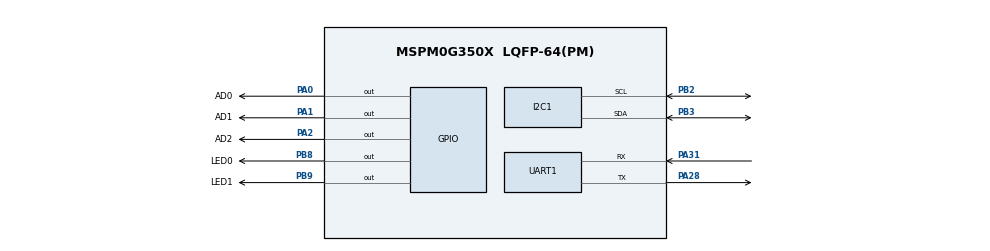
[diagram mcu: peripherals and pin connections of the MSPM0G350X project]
/**
 * ICM42688 软I2C + OLED 硬I2C1 — 地猛星 MSPM0G3507
 * OLED: I2C1, PB2=SCL, PB3=SDA, 地址0x3C
 * ICM: PA15=SCL, PA14=SDA, PA13=CS, PA16=AD0
 *
 * @cliArgs --device "MSPM0G350X" --part "Default" --package "LQFP-64(PM)"
 *            --product "mspm0_sdk@2.11.00.07"
 *             --product "mspm0_sdk@2.11.00.07"
 * @versions {"tool":"1.26.2+4477"}
 */

const GPIO    = scripting.addModule("/ti/driverlib/GPIO", {}, false);
const GPIO1   = GPIO.addInstance();     // LED
const GPIO2   = GPIO.addInstance();     // ICM_CS
const GPIO3   = GPIO.addInstance();     // ICM_SCL
const GPIO4   = GPIO.addInstance();     // ICM_SDA
const GPIO5   = GPIO.addInstance();     // ICM_AD0
const GPIO6   = GPIO.addInstance();     // GRAY address pins
const I2C     = scripting.addModule("/ti/driverlib/I2C", {}, false);
const I2C1    = I2C.addInstance();      // OLED
const SYSCTL  = scripting.addModule("/ti/driverlib/SYSCTL");
const SYSTICK = scripting.addModule("/ti/driverlib/SYSTICK");
const UART    = scripting.addModule("/ti/driverlib/UART", {}, false);
const UART1   = UART.addInstance();     // PRINT
const ADC12   = scripting.addModule("/ti/driverlib/ADC12", {}, false);
const ADC121  = ADC12.addInstance();    // GRAY_ADC

/* ========== 时钟 ========== */
const divider6       = system.clockTree["PLL_CLK2X_DIV"];
divider6.divideValue = 4;
const divider7       = system.clockTree["PLL_PDIV"];
divider7.divideValue = 2;
const divider9       = system.clockTree["UDIV"];
divider9.divideValue = 2;
const gate7  = system.clockTree["MFCLKGATE"];
gate7.enable = true;
const multiplier2         = system.clockTree["PLL_QDIV"];
multiplier2.multiplyValue = 10;
const mux8       = system.clockTree["HSCLKMUX"];
mux8.inputSelect = "HSCLKMUX_SYSPLL2X";

SYSCTL.forceDefaultClkConfig = true;
SYSCTL.clockTreeEn           = true;

const Board = scripting.addModule("/ti/driverlib/Board", {}, false);

/* ========== GPIO1: LED ========== */
GPIO1.$name                         = "LED";
GPIO1.associatedPins.create(2);
GPIO1.associatedPins[0].$name       = "LED0";
GPIO1.associatedPins[0].pin.$assign = "PB8";
GPIO1.associatedPins[1].$name       = "LED1";
GPIO1.associatedPins[1].pin.$assign = "PB9";

/* ========== GPIO2: ICM_CS (PA13, 输出HIGH→I2C模式) ========== */
GPIO2.$name                         = "ICM_CS";
GPIO2.port                          = "PORTA";
GPIO2.associatedPins[0].$name       = "CS";
GPIO2.associatedPins[0].assignedPin = "13";

/* ========== GPIO3: ICM_SCL (PA15, 软I2C时钟) ========== */
GPIO3.$name                         = "ICM_SCL";
GPIO3.port                          = "PORTA";
GPIO3.associatedPins[0].$name       = "SCL";
GPIO3.associatedPins[0].assignedPin = "15";

/* ========== GPIO4: ICM_SDA (PA14, 软I2C数据) ========== */
GPIO4.$name                         = "ICM_SDA";
GPIO4.port                          = "PORTA";
GPIO4.associatedPins[0].$name       = "SDA";
GPIO4.associatedPins[0].assignedPin = "14";

/* ========== GPIO5: ICM_AD0 (PA16, 输出LOW→地址0x68) ========== */
GPIO5.$name                         = "ICM_AD0";
GPIO5.port                          = "PORTA";
GPIO5.associatedPins[0].$name       = "AD0";
GPIO5.associatedPins[0].assignedPin = "16";

/* ========== GPIO6: 灰度模块通道地址 (PA0/PA1/PA2) ========== */
GPIO6.$name                         = "GRAY_ADDR";
GPIO6.port                          = "PORTA";
GPIO6.associatedPins.create(3);
GPIO6.associatedPins[0].$name       = "AD0";
GPIO6.associatedPins[0].assignedPin = "0";
GPIO6.associatedPins[0].pin.$assign = "PA0";
GPIO6.associatedPins[1].$name       = "AD1";
GPIO6.associatedPins[1].assignedPin = "1";
GPIO6.associatedPins[1].pin.$assign = "PA1";
GPIO6.associatedPins[2].$name       = "AD2";
GPIO6.associatedPins[2].assignedPin = "2";
GPIO6.associatedPins[2].pin.$assign = "PA2";

/* ========== ADC0: 灰度模块 OUT (PA27 / ADC channel 0) ========== */
ADC121.$name                      = "GRAY_ADC";
ADC121.sampClkSrc                 = "DL_ADC12_CLOCK_ULPCLK";
ADC121.sampClkDiv                 = "DL_ADC12_CLOCK_DIVIDE_8";
ADC121.adcMem0chansel             = "DL_ADC12_INPUT_CHAN_0";
ADC121.adcMem0_name               = "GRAY_ADC_MEM";
ADC121.sampleTime0                = "25 us";
ADC121.powerDownMode              = "DL_ADC12_POWER_DOWN_MODE_MANUAL";
ADC121.peripheral.$assign         = "ADC0";
ADC121.peripheral.adcPin0.$assign = "PA27";

/* ========== I2C1: OLED (PB2=SCL, PB3=SDA) ========== */
I2C1.$name                             = "OLED";
I2C1.basicEnableController             = true;
I2C1.advDigitalGlitchFilter            = "CLOCKS_1";
I2C1.advControllerRXFIFOTRIG           = "BYTES_8";
I2C1.advControllerTXFIFOTRIG           = "BYTES_7";
I2C1.peripheral.$assign                = "I2C1";
I2C1.peripheral.sdaPin.$assign         = "PB3";
I2C1.peripheral.sclPin.$assign         = "PB2";
I2C1.sdaPinConfig.$name                = "ti_driverlib_gpio_GPIOPinGeneric2";
I2C1.sdaPinConfig.hideOutputInversion  = scripting.forceWrite(false);
I2C1.sdaPinConfig.onlyInternalResistor = scripting.forceWrite(false);
I2C1.sdaPinConfig.passedPeripheralType = scripting.forceWrite("Digital");
I2C1.sdaPinConfig.enableConfig         = true;
I2C1.sdaPinConfig.internalResistor     = "PULL_UP";
I2C1.sclPinConfig.$name                = "ti_driverlib_gpio_GPIOPinGeneric3";
I2C1.sclPinConfig.hideOutputInversion  = scripting.forceWrite(false);
I2C1.sclPinConfig.onlyInternalResistor = scripting.forceWrite(false);
I2C1.sclPinConfig.passedPeripheralType = scripting.forceWrite("Digital");
I2C1.sclPinConfig.enableConfig         = true;
I2C1.sclPinConfig.internalResistor     = "PULL_UP";

/* ========== SysTick ========== */
SYSTICK.systickEnable     = true;
SYSTICK.periodEnable      = true;
SYSTICK.period            = 32;
SYSTICK.interruptPriority = "3";

/* ========== UART1: 调试串口 ========== */
UART1.$name                            = "PRINT";
UART1.uartClkSrc                       = "MFCLK";
UART1.targetBaudRate                   = 115200;
UART1.peripheral.$assign               = "UART0";
UART1.peripheral.rxPin.$assign         = "PA31";
UART1.peripheral.txPin.$assign         = "PA28";
UART1.txPinConfig.$name                = "ti_driverlib_gpio_GPIOPinGeneric0";
UART1.txPinConfig.direction            = scripting.forceWrite("OUTPUT");
UART1.txPinConfig.hideOutputInversion  = scripting.forceWrite(false);
UART1.txPinConfig.onlyInternalResistor = scripting.forceWrite(false);
UART1.txPinConfig.passedPeripheralType = scripting.forceWrite("Digital");
UART1.rxPinConfig.$name                = "ti_driverlib_gpio_GPIOPinGeneric1";
UART1.rxPinConfig.hideOutputInversion  = scripting.forceWrite(false);
UART1.rxPinConfig.onlyInternalResistor = scripting.forceWrite(false);
UART1.rxPinConfig.passedPeripheralType = scripting.forceWrite("Digital");

/* Pinmux */
Board.peripheral.$suggestSolution          = "DEBUGSS";
Board.peripheral.swclkPin.$suggestSolution = "PA20";
Board.peripheral.swdioPin.$suggestSolution = "PA19";
I2C1.peripheral.$suggestSolution           = "I2C1";
I2C1.peripheral.sdaPin.$suggestSolution    = "PB3";
I2C1.peripheral.sclPin.$suggestSolution    = "PB2";
GPIO2.associatedPins[0].pin.$suggestSolution  = "PA13";
GPIO3.associatedPins[0].pin.$suggestSolution  = "PA15";
GPIO4.associatedPins[0].pin.$suggestSolution  = "PA14";
GPIO5.associatedPins[0].pin.$suggestSolution  = "PA16";
GPIO6.associatedPins[0].pin.$suggestSolution  = "PA0";
GPIO6.associatedPins[1].pin.$suggestSolution  = "PA1";
GPIO6.associatedPins[2].pin.$suggestSolution  = "PA2";
ADC121.peripheral.$suggestSolution            = "ADC0";
ADC121.peripheral.adcPin0.$suggestSolution    = "PA27";
